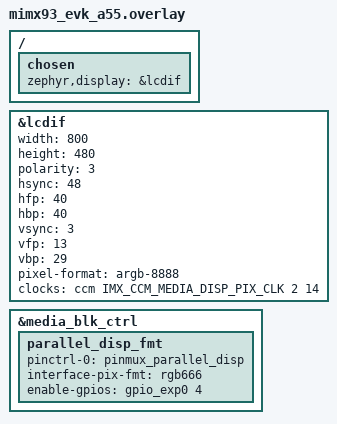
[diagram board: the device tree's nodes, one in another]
/*
 * Copyright 2023 NXP
 *
 * SPDX-License-Identifier: Apache-2.0
 */

/ {
	chosen {
		zephyr,display = &lcdif;
	};
};

&lcdif {
	width = <800>;
	height = <480>;
	polarity = <3>;
	hsync = <48>;
	hfp = <40>;
	hbp = <40>;
	vsync = <3>;
	vfp = <13>;
	vbp = <29>;
	pixel-format = "argb-8888";
	clocks = <&ccm IMX_CCM_MEDIA_DISP_PIX_CLK 2 14>; //kCLOCK_VideoPll1: 420MHz
	status = "okay";
};

&media_blk_ctrl {
	status = "okay";

	parallel_disp_fmt {
		pinctrl-names = "default";
		pinctrl-0 = <&pinmux_parallel_disp>;
		interface-pix-fmt = "rgb666";
		enable-gpios = <&gpio_exp0 4 GPIO_ACTIVE_HIGH>;
		status = "okay";
	};
};
